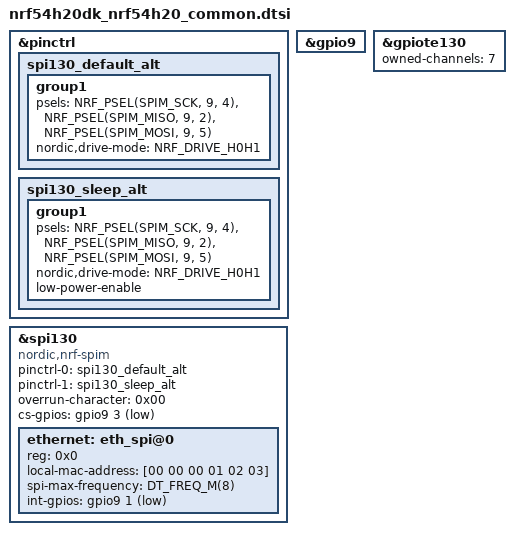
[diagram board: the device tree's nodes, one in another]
/*
 * Copyright (c) 2024 Nordic Semiconductor
 *
 * SPDX-License-Identifier: Apache-2.0
 */

&pinctrl {
	spi130_default_alt: spi130_default_alt {
		group1 {
			psels = <NRF_PSEL(SPIM_SCK, 9, 4)>,
				<NRF_PSEL(SPIM_MISO, 9, 2)>,
				<NRF_PSEL(SPIM_MOSI, 9, 5)>;
			nordic,drive-mode = <NRF_DRIVE_H0H1>;
		};
	};

	spi130_sleep_alt: spi130_sleep_alt {
		group1 {
			psels = <NRF_PSEL(SPIM_SCK, 9, 4)>,
				<NRF_PSEL(SPIM_MISO, 9, 2)>,
				<NRF_PSEL(SPIM_MOSI, 9, 5)>;
			nordic,drive-mode = <NRF_DRIVE_H0H1>;
			low-power-enable;
		};
	};

};

&gpio9 {
	status = "okay";
};

&gpiote130 {
	status = "okay";
	owned-channels = <7>;
};

&spi130 {
	compatible = "nordic,nrf-spim";
	status = "okay";
	pinctrl-0 = <&spi130_default_alt>;
	pinctrl-1 = <&spi130_sleep_alt>;
	pinctrl-names = "default", "sleep";
	overrun-character = <0x00>;
	cs-gpios = <&gpio9 3 GPIO_ACTIVE_LOW>;

	ethernet: eth_spi@0 {
		reg = <0x0>;
		local-mac-address = [00 00 00 01 02 03];
		spi-max-frequency = <DT_FREQ_M(8)>;
		int-gpios = <&gpio9 1 GPIO_ACTIVE_LOW>;	/* INT */
	};

};
